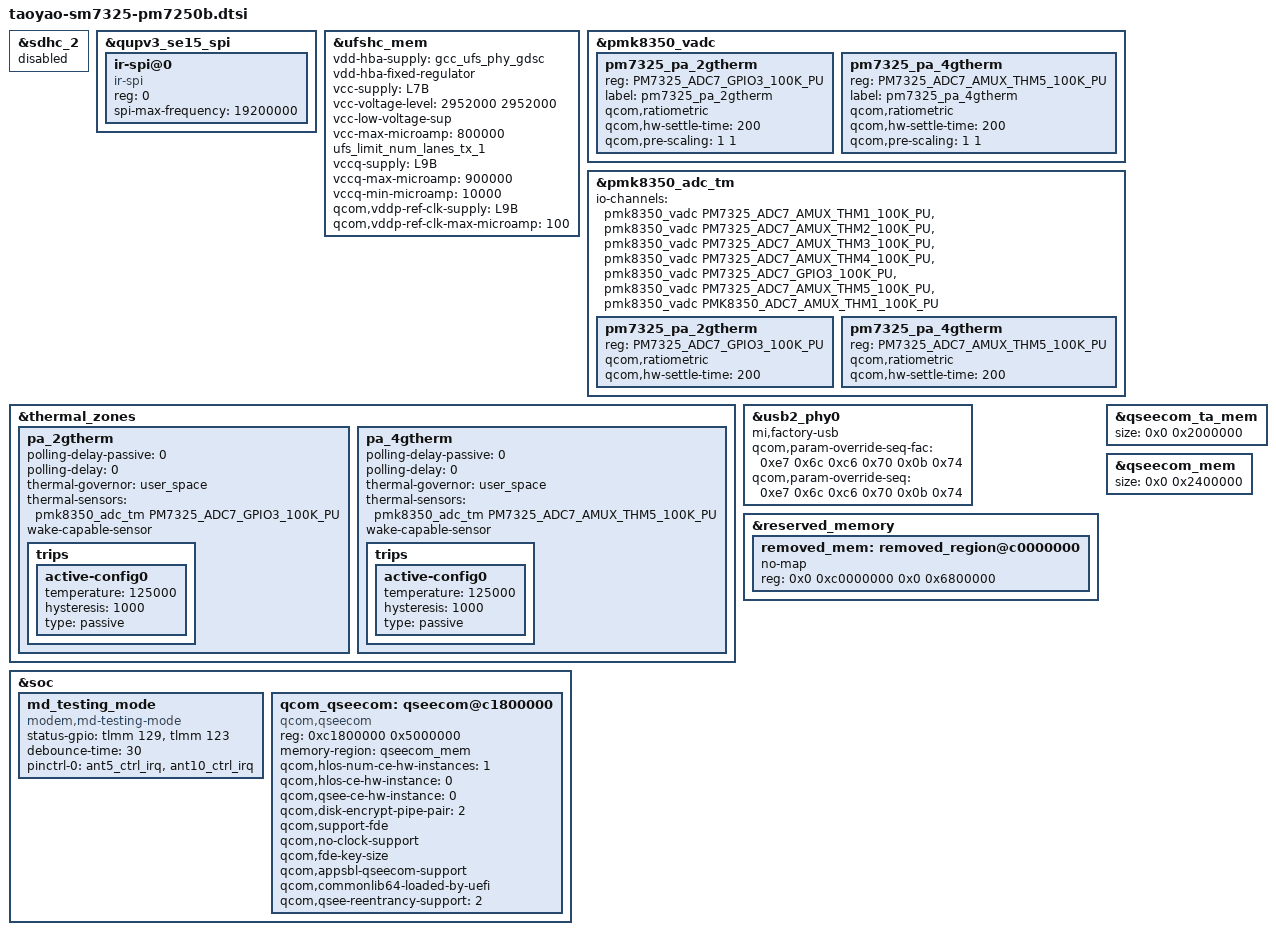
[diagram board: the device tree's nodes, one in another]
/*
this file is for attribution only of mona
And public attribution of xiaomi platforms
*/

#include "xiaomi-sm7325-pm7250b-common.dtsi"
#include "camera/taoyao-sm7325-camera-sensor.dtsi"
#include "taoyao-pinctrl.dtsi"
#include "taoyao-audio-overlay.dtsi"

&sdhc_2 {
	status = "disabled";
};

&qupv3_se15_spi {
	status = "ok";
	ir-spi@0 {
		compatible = "ir-spi";
		reg = <0>;
		spi-max-frequency = <19200000>;
		status = "ok";
	};
};

&ufshc_mem {
	vdd-hba-supply = <&gcc_ufs_phy_gdsc>;
	vdd-hba-fixed-regulator;

	vcc-supply = <&L7B>;
	vcc-voltage-level = <2952000 2952000>;
	vcc-low-voltage-sup;
	vcc-max-microamp = <800000>;

	ufs_limit_num_lanes_tx_1;

	/*
	 * Yupik target supports both UFS2.2 & UFS3.1, here
	 * vccq2 is supplied via eLDO, and that is controlled via
	 * L9B which supports a max voltage of 1.2V, but eLDO would
	 * supply 1.8V. and same L9B acts as vccq voltage for UFS3.1
	 * devices.
	 * Here L9B can max support for 1.2V but UFS GKI driver code
	 * votes for 1.8V, which is leading to failure from pmic
	 * regulator.
	 *
	 * Now since vccq and control of eLDO are common that is L9B
	 * we can use vccq vote as control of eLDO for vccq2.
	 * Hence vccq entries shall be used for both type of UFS
	 * devices only. And vccq entries should not be changed/removed
	 * for any design alteration.
	 */
	vccq-supply = <&L9B>;
	vccq-max-microamp = <900000>;
	vccq-min-microamp = <10000>;

	qcom,vddp-ref-clk-supply = <&L9B>;
	qcom,vddp-ref-clk-max-microamp = <100>;

	status = "ok";
};

&pmk8350_vadc {

	pm7325_pa_2gtherm {
		reg = <PM7325_ADC7_GPIO3_100K_PU>;
		label = "pm7325_pa_2gtherm";
		qcom,ratiometric;
		qcom,hw-settle-time = <200>;
		qcom,pre-scaling = <1 1>;
	};

	pm7325_pa_4gtherm {
		reg = <PM7325_ADC7_AMUX_THM5_100K_PU>;
		label = "pm7325_pa_4gtherm";
		qcom,ratiometric;
		qcom,hw-settle-time = <200>;
		qcom,pre-scaling = <1 1>;
	};
};

&pmk8350_adc_tm {
	io-channels = <&pmk8350_vadc PM7325_ADC7_AMUX_THM1_100K_PU>,
			<&pmk8350_vadc PM7325_ADC7_AMUX_THM2_100K_PU>,
			<&pmk8350_vadc PM7325_ADC7_AMUX_THM3_100K_PU>,
			<&pmk8350_vadc PM7325_ADC7_AMUX_THM4_100K_PU>,
			<&pmk8350_vadc PM7325_ADC7_GPIO3_100K_PU>,
			<&pmk8350_vadc PM7325_ADC7_AMUX_THM5_100K_PU>,
			<&pmk8350_vadc PMK8350_ADC7_AMUX_THM1_100K_PU>;

	pm7325_pa_2gtherm {
		reg = <PM7325_ADC7_GPIO3_100K_PU>;
		qcom,ratiometric;
		qcom,hw-settle-time = <200>;
	};

	pm7325_pa_4gtherm {
		reg = <PM7325_ADC7_AMUX_THM5_100K_PU>;
		qcom,ratiometric;
		qcom,hw-settle-time = <200>;
	};

};

&thermal_zones {

	pa_2gtherm {
		polling-delay-passive = <0>;
		polling-delay = <0>;
		thermal-governor = "user_space";
		thermal-sensors = <&pmk8350_adc_tm PM7325_ADC7_GPIO3_100K_PU>;
		wake-capable-sensor;
		trips {
			active-config0 {
				temperature = <125000>;
				hysteresis = <1000>;
				type = "passive";
			};
		};
	};

	pa_4gtherm {
		polling-delay-passive = <0>;
		polling-delay = <0>;
		thermal-governor = "user_space";
		thermal-sensors = <&pmk8350_adc_tm PM7325_ADC7_AMUX_THM5_100K_PU>;
		wake-capable-sensor;
		trips {
			active-config0 {
				temperature = <125000>;
				hysteresis = <1000>;
				type = "passive";
			};
		};
	};
};

&soc {
	md_testing_mode {
		compatible = "modem,md-testing-mode";
		status-gpio = <&tlmm 129 0x00>,
                      <&tlmm 123 0x00>;
		debounce-time = <30>;
		pinctrl-names = "default";
		pinctrl-0 = <&ant5_ctrl_irq &ant10_ctrl_irq>;
	};
};

&usb2_phy0 {
	mi,factory-usb;
	qcom,param-override-seq-fac =
		<0xe7 0x6c	/* override_x0 */
		0xc6 0x70	/* override_x1 */
		0x0b 0x74>;	/* override x2 */
	qcom,param-override-seq =
		<0xe7 0x6c	/* override_x0 */
		0xc6 0x70	/* override_x1 */
		0x0b 0x74>;	/* override x2 */
};

&reserved_memory {
  removed_mem: removed_region@c0000000 {
          no-map;
                  reg = <0x0 0xc0000000 0x0 0x6800000>;
        };
};

&soc {
        qcom_qseecom: qseecom@c1800000 {
  compatible = "qcom,qseecom";
        reg = <0xc1800000 0x5000000>;
        reg-names = "secapp-region";
        memory-region = <&qseecom_mem>;
        qcom,hlos-num-ce-hw-instances = <1>;
        qcom,hlos-ce-hw-instance = <0>;
        qcom,qsee-ce-hw-instance = <0>;
        qcom,disk-encrypt-pipe-pair = <2>;
        qcom,support-fde;
        qcom,no-clock-support;
        qcom,fde-key-size;
        qcom,appsbl-qseecom-support;
        qcom,commonlib64-loaded-by-uefi;
        qcom,qsee-reentrancy-support = <2>;
        };
};

&qseecom_ta_mem {
        size = <0x0 0x2000000>;
};

&qseecom_mem {
	size = <0x0 0x2400000>;
};
